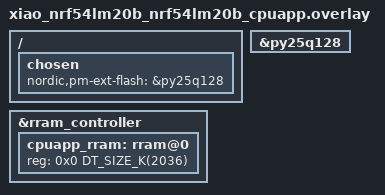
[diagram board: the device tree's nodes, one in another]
/* Allow MCUboot to access the PY25Q128HA secondary image slot. */

/ {
	chosen {
		nordic,pm-ext-flash = &py25q128;
	};
};

&rram_controller {
	cpuapp_rram: rram@0 {
		reg = <0x0 DT_SIZE_K(2036)>;
		ranges = <0x0 0x0 DT_SIZE_K(2036)>;
	};
};

&py25q128 {
	status = "okay";
};
